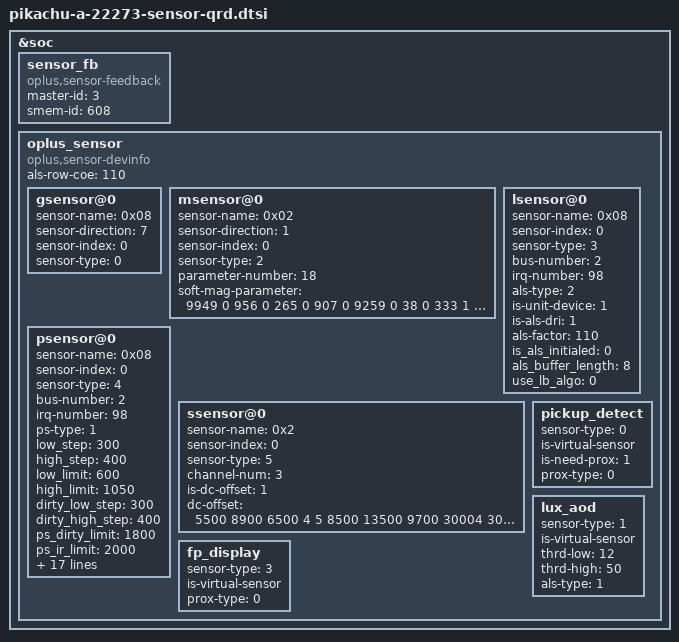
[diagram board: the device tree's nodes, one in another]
&soc {
	sensor_fb: sensor_fb {
		compatible = "oplus,sensor-feedback";
		master-id  = <3>;
		smem-id    = <608>;
	};
	oplus_sensor {
			compatible = "oplus,sensor-devinfo";
			als-row-coe = <110>;
			/*enum {LSM6DSM = 0x01, BMI160 = 0x02, LSM6DS3 = 0x04, BMI260 = 0x08};*/
			gsensor@0 {
					sensor-name = <0x08>;//BMI260
					sensor-direction = <7>;
					sensor-index = <0>;//source num
					sensor-type = <0>;//OPLUS_ACCEL
			};
			/* enum {AKM0991X = 0x01, MMC5603 = 0x02, MXG4300 = 0x04};*/
			msensor@0 {
					sensor-name = <0x02>;//MMC5603
					sensor-direction = <1>;
					sensor-index = <0>;
					sensor-type = <2>;//OPLUS_MAG
					parameter-number= <18>;
					soft-mag-parameter = <9949 0 956 0 265 0 907 0 9259 0 38 0 333 1 924 1 10940 0>;//e00 sign e01 sign...
			};
			/*enum {STK3A5X=0x01,TCS3701=0x02,TCS3408=0x04,STK326X=0x08,MN78911=0x10};*/
			/*enum {NORMAL=0x01,UNDER_LCD=0x02,VIRTUAL_UNDER_LCD=0x03}*/
			lsensor@0 {
					sensor-name = <0x08>;//STK326X
					sensor-index = <0>;
					sensor-type = <3>;//OPLUS_ALS
					bus-number = <2>;
					irq-number = <98>;
					als-type = <2>;//UNDER_LCD
					is-unit-device = <1>;
					is-als-dri = <1>;
					als-factor = <110>;
					is_als_initialed = <0>;
					als_buffer_length = <8>;
					use_lb_algo = <0>;
			};
			psensor@0 {
					sensor-name = <0x08>;//STK326X
					sensor-index = <0>;
					sensor-type = <4>;//OPLUS_PROXIMITY
					bus-number = <2>;
					irq-number = <98>;
					ps-type = <1>;
					low_step = <300>;
					high_step = <400>;
					low_limit = <600>;
					high_limit = <1050>;
					dirty_low_step = <300>;
					dirty_high_step = <400>;
					ps_dirty_limit = <1800>;
					ps_ir_limit = <2000>;
					ps_adjust_min = <0>;
					ps_adjust_max = <1850>;
					sampling_count = <5>;
					step_max = <400>;
					step_min = <100>;
					step_div = <2000>;
					anti_shake_delta = <70>;
					dynamic_cali_max = <2000>;
					raw2offset_radio = <1000>;
					offset_max = <60000>;
					offset_range_min = <0>;
					offset_range_max = <65535>;
					force_cali_limit = <2000>;
					cali_jitter_limit = <20>;
					cal_offset_margin = <3000>;
					/*sensor-reg start*/
					parameter-number = <6>;
					sensor-reg = <0x01 0x35
							0x03 0x20
							0xDB 0x00>; //override special reg
					/*sensor-reg end*/
			};
			ssensor@0 {
				sensor-name = <0x2>;//SX9331
				sensor-index = <0>;
				sensor-type = <5>;//OPLUS_SAR
				channel-num = <3>;
				is-dc-offset = <1>;
				dc-offset = <5500 8900 6500 4 5 8500 13500 9700 30004 30005>;
			};
			/*virtual sensor
			enum sensor_algo_id {
					OPLUS_PICKUP_DETECT,
					OPLUS_LUX_AOD,
					OPLUS_TP_GESTURE,
					OPLUS_FP_DISPLAY,
					OPLUS_FREE_FALL,
					OPLUS_CAMERA_PROTECT,
					SENSOR_ALGO_NUM
			}*/
			pickup_detect {
					sensor-type = <0>; //OPLUS_PICKUP_DETECT
					is-virtual-sensor;
					is-need-prox = <1>;
					prox-type = <0>; // 0 - proximity; 1 - proximity_fake
			};
			lux_aod {
				sensor-type = <1>; //OPLUS_LUX_AOD
				is-virtual-sensor;
				thrd-low = <12>;
				thrd-high = <50>;
				als-type = <1>;
			};
			fp_display {
				sensor-type = <3>;//OPLUS_FP_DISPLAY
				is-virtual-sensor;
				prox-type = <0>; // 0 - proximity; 1 - proximity_fake
			};
	};
};

